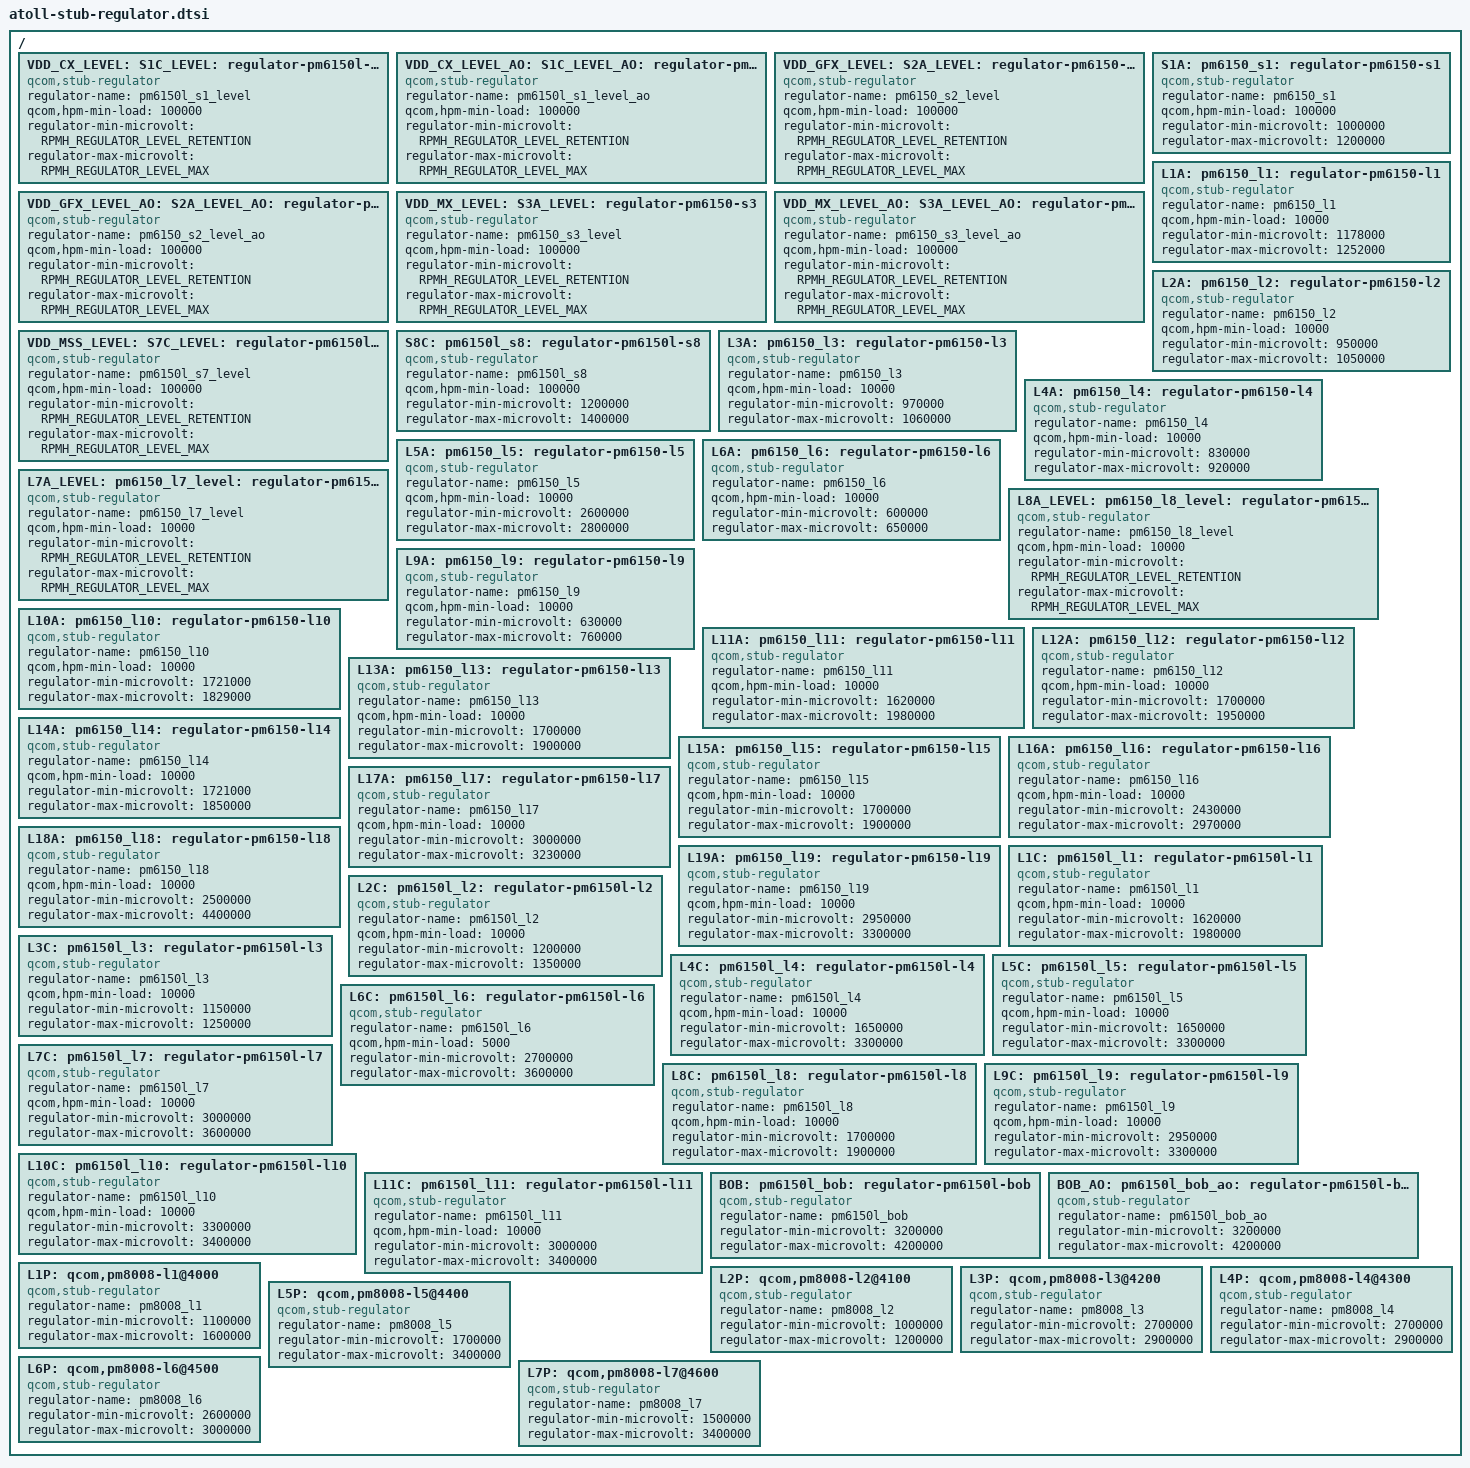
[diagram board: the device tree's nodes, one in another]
/* Copyright (c) 2019, The Linux Foundation. All rights reserved.
 *
 * This program is free software; you can redistribute it and/or modify
 * it under the terms of the GNU General Public License version 2 and
 * only version 2 as published by the Free Software Foundation.
 *
 * This program is distributed in the hope that it will be useful,
 * but WITHOUT ANY WARRANTY; without even the implied warranty of
 * MERCHANTABILITY or FITNESS FOR  PARTICULAR PURPOSE.  See the
 * GNU General Public License for more details.
 */

#include <dt-bindings/regulator/qcom,rpmh-regulator.h>

/* Stub regulators */

/ {
	/* pm6150l S1 - VDD_CX supply */
	VDD_CX_LEVEL:
	S1C_LEVEL: pm6150l_s1_level: regulator-pm6150l-s1 {
		compatible = "qcom,stub-regulator";
		regulator-name = "pm6150l_s1_level";
		qcom,hpm-min-load = <100000>;
		regulator-min-microvolt = <RPMH_REGULATOR_LEVEL_RETENTION>;
		regulator-max-microvolt = <RPMH_REGULATOR_LEVEL_MAX>;
	};

	VDD_CX_LEVEL_AO:
	S1C_LEVEL_AO: pm6150l_s1_level_ao: regulator-pm6150l-s1-level-ao {
		compatible = "qcom,stub-regulator";
		regulator-name = "pm6150l_s1_level_ao";
		qcom,hpm-min-load = <100000>;
		regulator-min-microvolt = <RPMH_REGULATOR_LEVEL_RETENTION>;
		regulator-max-microvolt = <RPMH_REGULATOR_LEVEL_MAX>;
	};

	/* pm6150 S2 - VDD_GFX supply */
	VDD_GFX_LEVEL:
	S2A_LEVEL: pm6150_s2_level: regulator-pm6150-s2 {
		compatible = "qcom,stub-regulator";
		regulator-name = "pm6150_s2_level";
		qcom,hpm-min-load = <100000>;
		regulator-min-microvolt = <RPMH_REGULATOR_LEVEL_RETENTION>;
		regulator-max-microvolt = <RPMH_REGULATOR_LEVEL_MAX>;
	};

	VDD_GFX_LEVEL_AO:
	S2A_LEVEL_AO: pm6150_s2_level_ao: regulator-pm6150-s2-level-ao {
		compatible = "qcom,stub-regulator";
		regulator-name = "pm6150_s2_level_ao";
		qcom,hpm-min-load = <100000>;
		regulator-min-microvolt = <RPMH_REGULATOR_LEVEL_RETENTION>;
		regulator-max-microvolt = <RPMH_REGULATOR_LEVEL_MAX>;
	};

	/* pm6150 S3 - VDD_MX supply */
	VDD_MX_LEVEL:
	S3A_LEVEL: pm6150_s3_level: regulator-pm6150-s3 {
		compatible = "qcom,stub-regulator";
		regulator-name = "pm6150_s3_level";
		qcom,hpm-min-load = <100000>;
		regulator-min-microvolt = <RPMH_REGULATOR_LEVEL_RETENTION>;
		regulator-max-microvolt = <RPMH_REGULATOR_LEVEL_MAX>;
	};

	VDD_MX_LEVEL_AO:
	S3A_LEVEL_AO: pm6150_s3_level_ao: regulator-pm6150-s3-level-ao {
		compatible = "qcom,stub-regulator";
		regulator-name = "pm6150_s3_level_ao";
		qcom,hpm-min-load = <100000>;
		regulator-min-microvolt = <RPMH_REGULATOR_LEVEL_RETENTION>;
		regulator-max-microvolt = <RPMH_REGULATOR_LEVEL_MAX>;
	};

	S1A: pm6150_s1: regulator-pm6150-s1 {
		compatible = "qcom,stub-regulator";
		regulator-name = "pm6150_s1";
		qcom,hpm-min-load = <100000>;
		regulator-min-microvolt = <1000000>;
		regulator-max-microvolt = <1200000>;
	};

	/* pm6150l S7 - VDD_MSS supply */
	VDD_MSS_LEVEL:
	S7C_LEVEL: pm6150l_s7_level: regulator-pm6150l-s7 {
		compatible = "qcom,stub-regulator";
		regulator-name = "pm6150l_s7_level";
		qcom,hpm-min-load = <100000>;
		regulator-min-microvolt = <RPMH_REGULATOR_LEVEL_RETENTION>;
		regulator-max-microvolt = <RPMH_REGULATOR_LEVEL_MAX>;
	};

	S8C: pm6150l_s8: regulator-pm6150l-s8 {
		compatible = "qcom,stub-regulator";
		regulator-name = "pm6150l_s8";
		qcom,hpm-min-load = <100000>;
		regulator-min-microvolt = <1200000>;
		regulator-max-microvolt = <1400000>;
	};

	L1A: pm6150_l1: regulator-pm6150-l1 {
		compatible = "qcom,stub-regulator";
		regulator-name = "pm6150_l1";
		qcom,hpm-min-load = <10000>;
		regulator-min-microvolt = <1178000>;
		regulator-max-microvolt = <1252000>;
	};

	L2A: pm6150_l2: regulator-pm6150-l2 {
		compatible = "qcom,stub-regulator";
		regulator-name = "pm6150_l2";
		qcom,hpm-min-load = <10000>;
		regulator-min-microvolt = <950000>;
		regulator-max-microvolt = <1050000>;
	};

	L3A: pm6150_l3: regulator-pm6150-l3 {
		compatible = "qcom,stub-regulator";
		regulator-name = "pm6150_l3";
		qcom,hpm-min-load = <10000>;
		regulator-min-microvolt = <970000>;
		regulator-max-microvolt = <1060000>;
	};

	L4A: pm6150_l4: regulator-pm6150-l4 {
		compatible = "qcom,stub-regulator";
		regulator-name = "pm6150_l4";
		qcom,hpm-min-load = <10000>;
		regulator-min-microvolt = <830000>;
		regulator-max-microvolt = <920000>;
	};

	L5A: pm6150_l5: regulator-pm6150-l5 {
		compatible = "qcom,stub-regulator";
		regulator-name = "pm6150_l5";
		qcom,hpm-min-load = <10000>;
		regulator-min-microvolt = <2600000>;
		regulator-max-microvolt = <2800000>;
	};

	L6A: pm6150_l6: regulator-pm6150-l6 {
		compatible = "qcom,stub-regulator";
		regulator-name = "pm6150_l6";
		qcom,hpm-min-load = <10000>;
		regulator-min-microvolt = <600000>;
		regulator-max-microvolt = <650000>;
	};

	/* pm6150 L7 - LPI_MX supply */
	L7A_LEVEL: pm6150_l7_level: regulator-pm6150-l7 {
		compatible = "qcom,stub-regulator";
		regulator-name = "pm6150_l7_level";
		qcom,hpm-min-load = <10000>;
		regulator-min-microvolt = <RPMH_REGULATOR_LEVEL_RETENTION>;
		regulator-max-microvolt = <RPMH_REGULATOR_LEVEL_MAX>;
	};

	/* pm6150 L8 - LPI_CX supply */
	L8A_LEVEL: pm6150_l8_level: regulator-pm6150-l8 {
		compatible = "qcom,stub-regulator";
		regulator-name = "pm6150_l8_level";
		qcom,hpm-min-load = <10000>;
		regulator-min-microvolt = <RPMH_REGULATOR_LEVEL_RETENTION>;
		regulator-max-microvolt = <RPMH_REGULATOR_LEVEL_MAX>;
	};

	L9A: pm6150_l9: regulator-pm6150-l9 {
		compatible = "qcom,stub-regulator";
		regulator-name = "pm6150_l9";
		qcom,hpm-min-load = <10000>;
		regulator-min-microvolt = <630000>;
		regulator-max-microvolt = <760000>;
	};

	L10A: pm6150_l10: regulator-pm6150-l10 {
		compatible = "qcom,stub-regulator";
		regulator-name = "pm6150_l10";
		qcom,hpm-min-load = <10000>;
		regulator-min-microvolt = <1721000>;
		regulator-max-microvolt = <1829000>;
	};

	L11A: pm6150_l11: regulator-pm6150-l11 {
		compatible = "qcom,stub-regulator";
		regulator-name = "pm6150_l11";
		qcom,hpm-min-load = <10000>;
		regulator-min-microvolt = <1620000>;
		regulator-max-microvolt = <1980000>;
	};

	L12A: pm6150_l12: regulator-pm6150-l12 {
		compatible = "qcom,stub-regulator";
		regulator-name = "pm6150_l12";
		qcom,hpm-min-load = <10000>;
		regulator-min-microvolt = <1700000>;
		regulator-max-microvolt = <1950000>;
	};

	L13A: pm6150_l13: regulator-pm6150-l13 {
		compatible = "qcom,stub-regulator";
		regulator-name = "pm6150_l13";
		qcom,hpm-min-load = <10000>;
		regulator-min-microvolt = <1700000>;
		regulator-max-microvolt = <1900000>;
	};

	L14A: pm6150_l14: regulator-pm6150-l14 {
		compatible = "qcom,stub-regulator";
		regulator-name = "pm6150_l14";
		qcom,hpm-min-load = <10000>;
		regulator-min-microvolt = <1721000>;
		regulator-max-microvolt = <1850000>;
	};

	L15A: pm6150_l15: regulator-pm6150-l15 {
		compatible = "qcom,stub-regulator";
		regulator-name = "pm6150_l15";
		qcom,hpm-min-load = <10000>;
		regulator-min-microvolt = <1700000>;
		regulator-max-microvolt = <1900000>;
	};

	L16A: pm6150_l16: regulator-pm6150-l16 {
		compatible = "qcom,stub-regulator";
		regulator-name = "pm6150_l16";
		qcom,hpm-min-load = <10000>;
		regulator-min-microvolt = <2430000>;
		regulator-max-microvolt = <2970000>;
	};

	L17A: pm6150_l17: regulator-pm6150-l17 {
		compatible = "qcom,stub-regulator";
		regulator-name = "pm6150_l17";
		qcom,hpm-min-load = <10000>;
		regulator-min-microvolt = <3000000>;
		regulator-max-microvolt = <3230000>;
	};

	L18A: pm6150_l18: regulator-pm6150-l18 {
		compatible = "qcom,stub-regulator";
		regulator-name = "pm6150_l18";
		qcom,hpm-min-load = <10000>;
		regulator-min-microvolt = <2500000>;
		regulator-max-microvolt = <4400000>;
	};

	L19A: pm6150_l19: regulator-pm6150-l19 {
		compatible = "qcom,stub-regulator";
		regulator-name = "pm6150_l19";
		qcom,hpm-min-load = <10000>;
		regulator-min-microvolt = <2950000>;
		regulator-max-microvolt = <3300000>;
	};

	L1C: pm6150l_l1: regulator-pm6150l-l1 {
		compatible = "qcom,stub-regulator";
		regulator-name = "pm6150l_l1";
		qcom,hpm-min-load = <10000>;
		regulator-min-microvolt = <1620000>;
		regulator-max-microvolt = <1980000>;
	};

	L2C: pm6150l_l2: regulator-pm6150l-l2 {
		compatible = "qcom,stub-regulator";
		regulator-name = "pm6150l_l2";
		qcom,hpm-min-load = <10000>;
		regulator-min-microvolt = <1200000>;
		regulator-max-microvolt = <1350000>;
	};

	L3C: pm6150l_l3: regulator-pm6150l-l3 {
		compatible = "qcom,stub-regulator";
		regulator-name = "pm6150l_l3";
		qcom,hpm-min-load = <10000>;
		regulator-min-microvolt = <1150000>;
		regulator-max-microvolt = <1250000>;
	};

	L4C: pm6150l_l4: regulator-pm6150l-l4 {
		compatible = "qcom,stub-regulator";
		regulator-name = "pm6150l_l4";
		qcom,hpm-min-load = <10000>;
		regulator-min-microvolt = <1650000>;
		regulator-max-microvolt = <3300000>;
	};

	L5C: pm6150l_l5: regulator-pm6150l-l5 {
		compatible = "qcom,stub-regulator";
		regulator-name = "pm6150l_l5";
		qcom,hpm-min-load = <10000>;
		regulator-min-microvolt = <1650000>;
		regulator-max-microvolt = <3300000>;
	};

	L6C: pm6150l_l6: regulator-pm6150l-l6 {
		compatible = "qcom,stub-regulator";
		regulator-name = "pm6150l_l6";
		qcom,hpm-min-load = <5000>;
		regulator-min-microvolt = <2700000>;
		regulator-max-microvolt = <3600000>;
	};

	L7C: pm6150l_l7: regulator-pm6150l-l7 {
		compatible = "qcom,stub-regulator";
		regulator-name = "pm6150l_l7";
		qcom,hpm-min-load = <10000>;
		regulator-min-microvolt = <3000000>;
		regulator-max-microvolt = <3600000>;
	};

	L8C: pm6150l_l8: regulator-pm6150l-l8 {
		compatible = "qcom,stub-regulator";
		regulator-name = "pm6150l_l8";
		qcom,hpm-min-load = <10000>;
		regulator-min-microvolt = <1700000>;
		regulator-max-microvolt = <1900000>;
	};

	L9C: pm6150l_l9: regulator-pm6150l-l9 {
		compatible = "qcom,stub-regulator";
		regulator-name = "pm6150l_l9";
		qcom,hpm-min-load = <10000>;
		regulator-min-microvolt = <2950000>;
		regulator-max-microvolt = <3300000>;
	};

	L10C: pm6150l_l10: regulator-pm6150l-l10 {
		compatible = "qcom,stub-regulator";
		regulator-name = "pm6150l_l10";
		qcom,hpm-min-load = <10000>;
		regulator-min-microvolt = <3300000>;
		regulator-max-microvolt = <3400000>;
	};

	L11C: pm6150l_l11: regulator-pm6150l-l11 {
		compatible = "qcom,stub-regulator";
		regulator-name = "pm6150l_l11";
		qcom,hpm-min-load = <10000>;
		regulator-min-microvolt = <3000000>;
		regulator-max-microvolt = <3400000>;
	};

	BOB: pm6150l_bob: regulator-pm6150l-bob {
		compatible = "qcom,stub-regulator";
		regulator-name = "pm6150l_bob";
		regulator-min-microvolt = <3200000>;
		regulator-max-microvolt = <4200000>;
	};

	BOB_AO: pm6150l_bob_ao: regulator-pm6150l-bob-ao {
		compatible = "qcom,stub-regulator";
		regulator-name = "pm6150l_bob_ao";
		regulator-min-microvolt = <3200000>;
		regulator-max-microvolt = <4200000>;
	};

	L1P: qcom,pm8008-l1@4000 {
		compatible = "qcom,stub-regulator";
		regulator-name = "pm8008_l1";
		regulator-min-microvolt = <1100000>;
		regulator-max-microvolt = <1600000>;
	};

	L2P: qcom,pm8008-l2@4100 {
		compatible = "qcom,stub-regulator";
		regulator-name = "pm8008_l2";
		regulator-min-microvolt = <1000000>;
		regulator-max-microvolt = <1200000>;
	};

	L3P: qcom,pm8008-l3@4200 {
		compatible = "qcom,stub-regulator";
		regulator-name = "pm8008_l3";
		regulator-min-microvolt = <2700000>;
		regulator-max-microvolt = <2900000>;
	};

	L4P: qcom,pm8008-l4@4300 {
		compatible = "qcom,stub-regulator";
		regulator-name = "pm8008_l4";
		regulator-min-microvolt = <2700000>;
		regulator-max-microvolt = <2900000>;
	};

	L5P: qcom,pm8008-l5@4400 {
		compatible = "qcom,stub-regulator";
		regulator-name = "pm8008_l5";
		regulator-min-microvolt = <1700000>;
		regulator-max-microvolt = <3400000>;
	};

	L6P: qcom,pm8008-l6@4500 {
		compatible = "qcom,stub-regulator";
		regulator-name = "pm8008_l6";
		regulator-min-microvolt = <2600000>;
		regulator-max-microvolt = <3000000>;
	};

	L7P: qcom,pm8008-l7@4600 {
		compatible = "qcom,stub-regulator";
		regulator-name = "pm8008_l7";
		regulator-min-microvolt = <1500000>;
		regulator-max-microvolt = <3400000>;
	};
};
